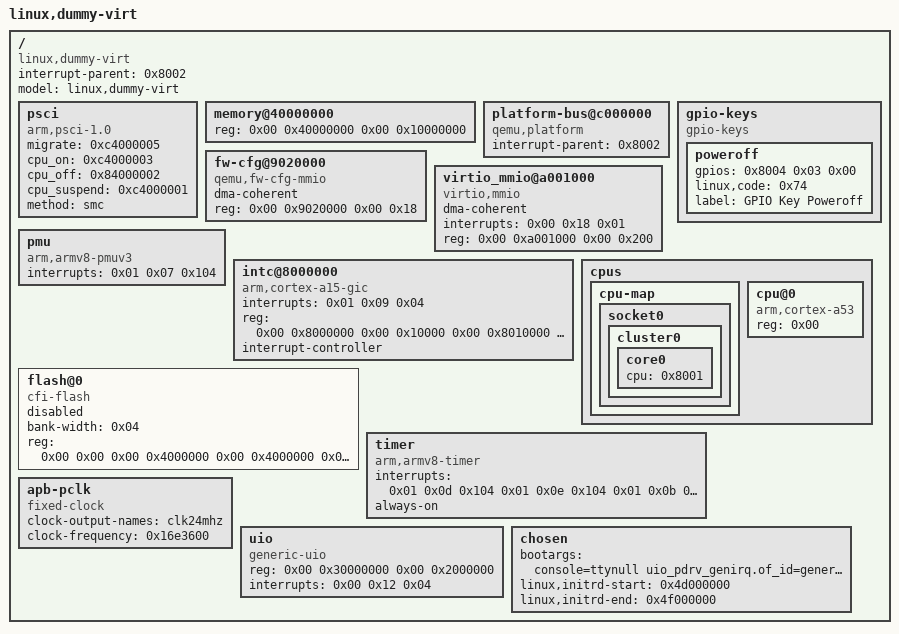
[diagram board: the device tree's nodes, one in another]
/dts-v1/;

/ {
	interrupt-parent = <0x8002>;
	model = "linux,dummy-virt";
	#size-cells = <0x02>;
	#address-cells = <0x02>;
	compatible = "linux,dummy-virt";

	psci {
		migrate = <0xc4000005>;
		cpu_on = <0xc4000003>;
		cpu_off = <0x84000002>;
		cpu_suspend = <0xc4000001>;
		method = "smc";
		compatible = "arm,psci-1.0\0arm,psci-0.2\0arm,psci";
	};

	memory@40000000 {
		reg = <0x00 0x40000000 0x00 0x10000000>;
		device_type = "memory";
	};

	platform-bus@c000000 {
		interrupt-parent = <0x8002>;
		ranges = <0x00 0x00 0xc000000 0x2000000>;
		#address-cells = <0x01>;
		#size-cells = <0x01>;
		compatible = "qemu,platform\0simple-bus";
	};

	fw-cfg@9020000 {
		dma-coherent;
		reg = <0x00 0x9020000 0x00 0x18>;
		compatible = "qemu,fw-cfg-mmio";
	};

	virtio_mmio@a001000 {
		dma-coherent;
		interrupts = <0x00 0x18 0x01>;
		reg = <0x00 0xa001000 0x00 0x200>;
		compatible = "virtio,mmio";
	};

	gpio-keys {
		compatible = "gpio-keys";

		poweroff {
			gpios = <0x8004 0x03 0x00>;
			linux,code = <0x74>;
			label = "GPIO Key Poweroff";
		};
	};

	pmu {
		interrupts = <0x01 0x07 0x104>;
		compatible = "arm,armv8-pmuv3";
	};

	intc@8000000 {
		phandle = <0x8002>;
		interrupts = <0x01 0x09 0x04>;
		reg = <0x00 0x8000000 0x00 0x10000 0x00 0x8010000 0x00 0x10000 0x00 0x8030000 0x00 0x10000 0x00 0x8040000 0x00 0x10000>;
		compatible = "arm,cortex-a15-gic";
		ranges;
		#size-cells = <0x02>;
		#address-cells = <0x02>;
		interrupt-controller;
		#interrupt-cells = <0x03>;
	};

	flash@0 {
		bank-width = <0x04>;
		reg = <0x00 0x00 0x00 0x4000000 0x00 0x4000000 0x00 0x4000000>;
		compatible = "cfi-flash";
		status = "disabled";
	};

	cpus {
		#size-cells = <0x00>;
		#address-cells = <0x01>;

		cpu-map {

			socket0 {

				cluster0 {

					core0 {
						cpu = <0x8001>;
					};
				};
			};
		};

		cpu@0 {
			phandle = <0x8001>;
			reg = <0x00>;
			compatible = "arm,cortex-a53";
			device_type = "cpu";
		};
	};

	timer {
		interrupts = <0x01 0x0d 0x104 0x01 0x0e 0x104 0x01 0x0b 0x104 0x01 0x0a 0x104>;
		always-on;
		compatible = "arm,armv8-timer\0arm,armv7-timer";
	};

	apb-pclk {
		phandle = <0x8000>;
		clock-output-names = "clk24mhz";
		clock-frequency = <0x16e3600>;
		#clock-cells = <0x00>;
		compatible = "fixed-clock";
	};

	uio {
		compatible = "generic-uio\0uio";
		reg = <0x00 0x30000000 0x00 0x2000000>;
		interrupts = <0x00 0x12 0x04>;
	};

	chosen {
		bootargs = "console=ttynull uio_pdrv_genirq.of_id=generic-uio vt.global_cursor_default=0 logo.nologo";
		linux,initrd-start = <0x4d000000>;
		linux,initrd-end = <0x4f000000>;
	};
};
